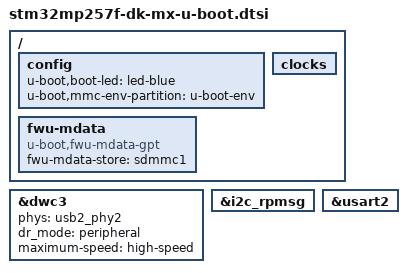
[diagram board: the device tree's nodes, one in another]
// SPDX-License-Identifier: (GPL-2.0-only OR BSD-3-Clause)
/*
 * Copyright (C) 2026, STMicroelectronics - All Rights Reserved
 * Author: STM32CubeMX code generation for STMicroelectronics.
 */

/* For more information on Device Tree configuration, please refer to
 * https://wiki.st.com/stm32mpu/wiki/Category:Device_tree_configuration
 */

#include "stm32mp25-u-boot.dtsi"

/* USER CODE BEGIN includes */
/* USER CODE END includes */

/ {

	/* USER CODE BEGIN root */

	config{
		u-boot,boot-led = "led-blue";
		u-boot,mmc-env-partition = "u-boot-env";
	};

	fwu-mdata{
		compatible = "u-boot,fwu-mdata-gpt";
		fwu-mdata-store = <&sdmmc1>;
	};
	/* USER CODE END root */

	clocks{

		/* USER CODE BEGIN clocks */
		/* USER CODE END clocks */
	};

}; /*root*/

/* USER CODE BEGIN addons */

&dwc3 {
	phys = <&usb2_phy2>;
	phy-names = "usb2-phy";
	dr_mode = "peripheral";
	maximum-speed = "high-speed";
	/delete-node/ port;
};

&i2c_rpmsg {
	/delete-node/ typec@35;
};


&usart2 {
	bootph-all;
};
/* USER CODE END addons */

